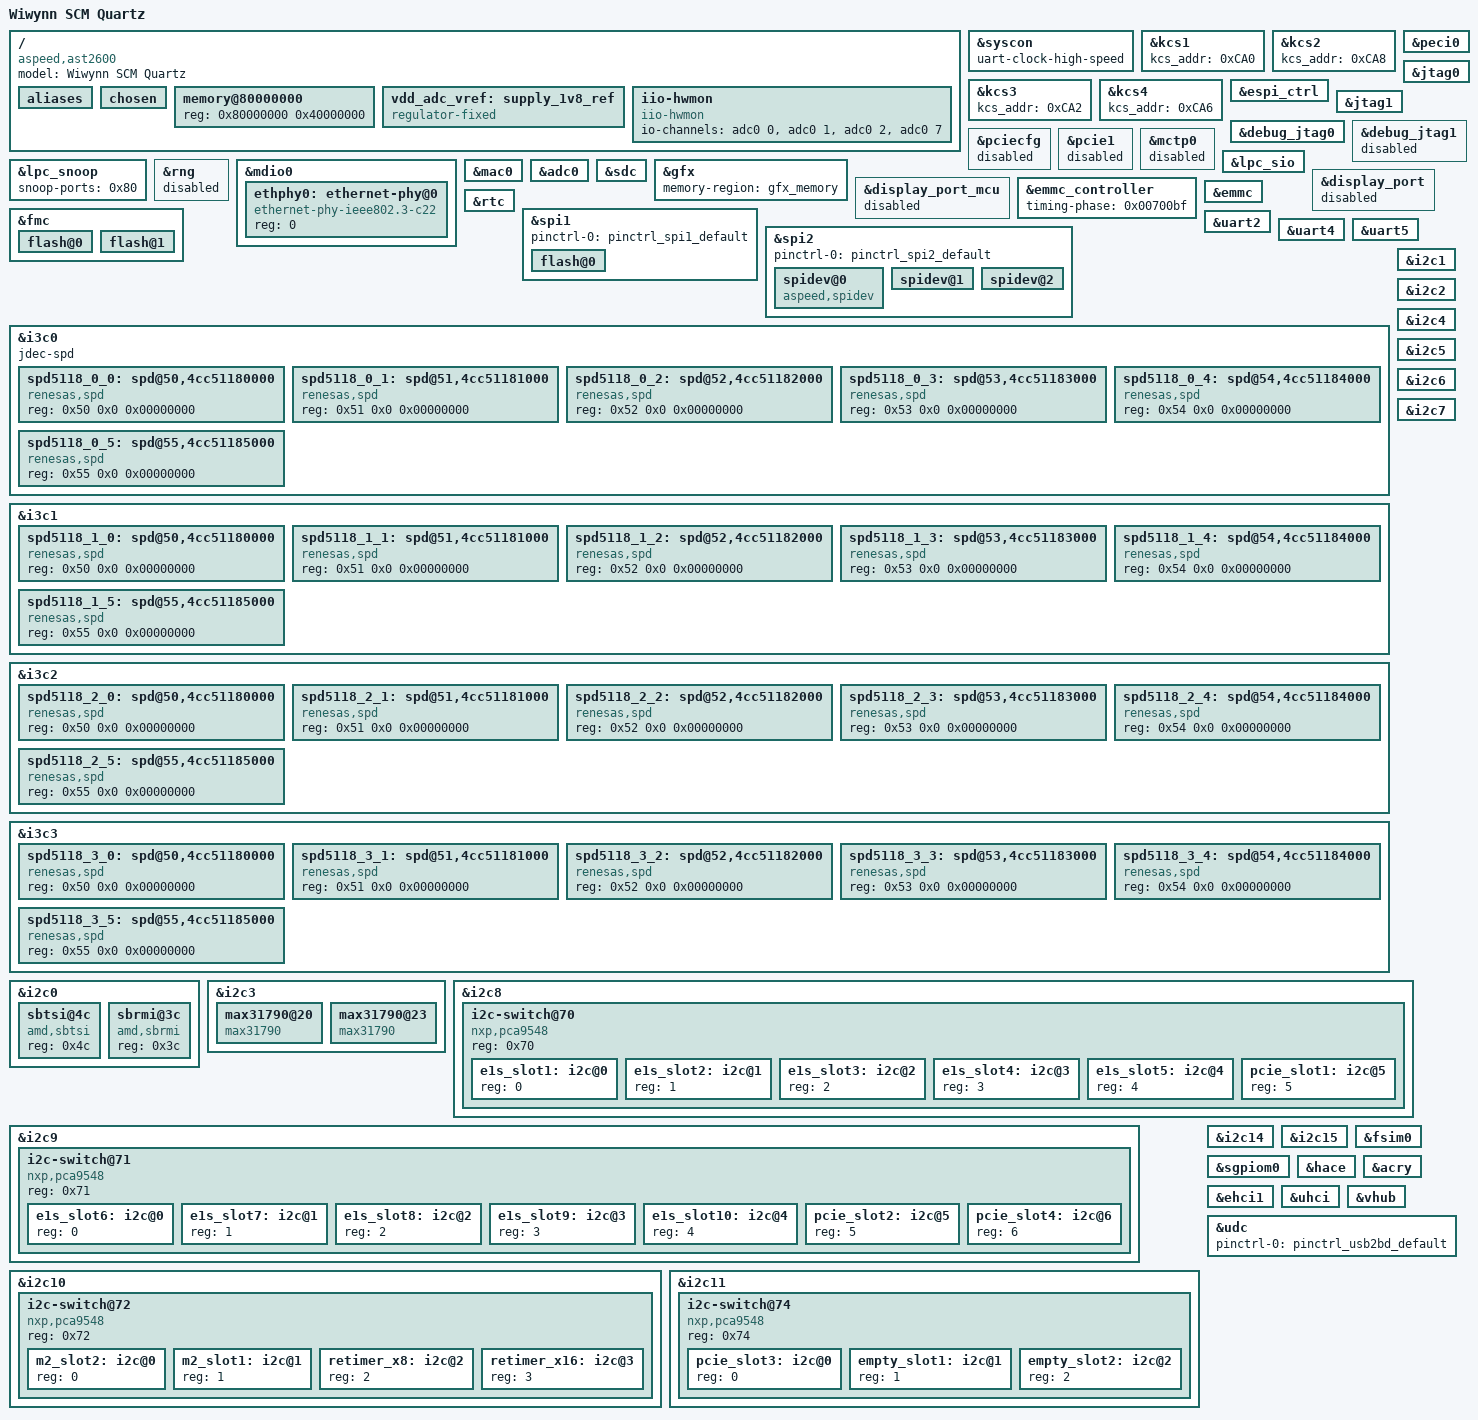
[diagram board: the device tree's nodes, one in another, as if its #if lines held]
// SPDX-License-Identifier: GPL-2.0-or-later
// Copyright 2019 IBM Corp.

/dts-v1/;

#include "aspeed-g6.dtsi"
#include <dt-bindings/gpio/aspeed-gpio.h>
#include <dt-bindings/i2c/i2c.h>

/ {
        model = "Wiwynn SCM Quartz";
        compatible = "aspeed,ast2600";

        aliases {
                serial0 = &uart1;
                serial1 = &uart2;
                serial2 = &uart3;
                serial3 = &uart4;
                serial4 = &uart5;
                i2c16 = &e1s_slot1;
                i2c17 = &e1s_slot2;
                i2c18 = &e1s_slot3;
                i2c19 = &e1s_slot4;
                i2c20 = &e1s_slot5;
                i2c21 = &pcie_slot1;
                i2c22 = &e1s_slot6;
                i2c23 = &e1s_slot7;
                i2c24 = &e1s_slot8;
                i2c25 = &e1s_slot9;
                i2c26 = &e1s_slot10;
                i2c27 = &pcie_slot2;
                i2c28 = &pcie_slot4;
                i2c29 = &m2_slot1;
                i2c30 = &m2_slot2;
                i2c31 = &retimer_x8;
                i2c32 = &retimer_x16;
                i2c33 = &pcie_slot3;
                i2c34 = &empty_slot1;
                i2c35 = &empty_slot2;
        };

        chosen {
		stdout-path = &uart5;
                bootargs = "console=ttyS4,115200n8";
        };

        memory@80000000 {
                device_type = "memory";
                reg = <0x80000000 0x40000000>;
        };
        vdd_adc_vref: supply_1v8_ref {
                compatible = "regulator-fixed";
                regulator-name = "adc-vref";
                regulator-min-microvolt = <1800000>;
                regulator-max-microvolt = <1800000>;
                regulator-always-on;
        };
    
        iio-hwmon {
                compatible = "iio-hwmon";
                io-channels = <&adc0 0>, <&adc0 1>, <&adc0 2>, <&adc0 7>;
        };

};

&syscon {
        uart-clock-high-speed;
        status = "okay";
};

#if 0
&lpc_pcc {
	dma-mode;
	memory-region = <&pcc_memory>;
    rec-mode = <0x1>;
    port-addr = <0x80>;
    port-addr-hbits-select = <0x1>;
    port-addr-xbits = <0x3>;
    status = "okay";
};

#endif

&kcs1 {
        kcs_addr = <0xCA0>;
        status = "okay";
};

&kcs2 {
        kcs_addr = <0xCA8>;
        status = "okay";
};

&kcs3 {
        kcs_addr = <0xCA2>;
        status = "okay";
};

&kcs4 {
        kcs_addr = <0xCA6>;
        status = "okay";
};

&peci0 {
        status = "okay";
};

#ifdef CONFIG_AMI
&espi_ctrl {
        status = "okay";

        perif,memcyc-src-addr = <0x98000000>;
        perif,memcyc-size = <0x10000>;
        perif,dma-mode;

        oob,dma-mode;
        oob,dma-tx-desc-num = <0x2>;
        oob,dma-rx-desc-num = <0x8>;

        flash,dma-mode;
        flash,safs-mode = <0x2>;

        aspeed,scu = <&syscon>;
};

&jtag0 {
        status = "okay";
};

&jtag1 {
        status = "okay";
};
#endif

#ifdef CONFIG_SPX_FEATURE_GLOBAL_AMD_REMOTE_DBG_SUPPORT
&debug_jtag0 {
        status = "okay";
};

&debug_jtag1 {
        status = "disabled";
};
#endif

#ifdef CONFIG_AMI
&pciecfg {
        status = "disabled";
};

&pcie1 {
        status = "disabled";
};

&mctp0 {
        tx-payload-bytes= <64>;
        rx-payload-bytes= <64>;
        status = "disabled";
};

&lpc_sio {
        status = "okay";
};
#endif

&lpc_snoop {
        snoop-ports = <0x80>;
        status = "okay";
};

&rng {
        status = "disabled";
};

&mdio0 {
        status = "okay";

        ethphy0: ethernet-phy@0 {
                compatible = "ethernet-phy-ieee802.3-c22";
                reg = <0>;
        };
};

&mac0 {
        status = "okay";

        phy-mode = "rgmii-rxid";
        phy-handle = <&ethphy0>;

        pinctrl-names = "default";
        pinctrl-0 = <&pinctrl_rgmii1_default>;
};

&adc0 {
        status = "okay";
        //aspeed,int-vref-microvolt = <1800000>;

        /*If you want to set external reference voltage(i.e. not 1.2V or 2.5V).
        You should add vref-supply property as below and set the microvolt 
        value at vdd_adc_vref node.*/
        vref-supply = <&vdd_adc_vref>;
        pinctrl-names = "default";
        pinctrl-0 = <&pinctrl_adc0_default &pinctrl_adc1_default
        &pinctrl_adc2_default &pinctrl_adc7_default>;
};

&sdc {
        status = "okay";
};

#ifdef CONFIG_AMI
&gfx {
        status = "okay";
        memory-region = <&gfx_memory>;
};

&display_port
{
        status = "disabled";
};

&display_port_mcu
{
        status = "disabled";
};

&emmc_controller {
        status = "okay";
        timing-phase = <0x00700bf>;
};

&emmc {
        status = "okay";
        non-removable;
        max-frequency = <100000000>;
        sdhci-drive-type = /bits/ 8 <3>;

        bus-width = <8>;
        pinctrl-0 = <&pinctrl_emmc_default
        &pinctrl_emmcg8_default>;
};
#endif

&rtc {
        status = "okay";
};

&fmc {
	status = "okay";

	flash@0 {
		status = "okay";
		m25p,fast-read;
		label = "bmc";
		spi-max-frequency = <133000000>;
#include "openbmc-flash-layout-64.dtsi"
	};

	flash@1 {
		status = "okay";
		m25p,fast-read;
		label = "alt-bmc";
		spi-max-frequency = <133000000>;
#include "openbmc-flash-layout-64-alt.dtsi"
	};
};

&spi1 {
	status = "okay";
	pinctrl-names = "default";
	pinctrl-0 = <&pinctrl_spi1_default>;

	flash@0 {
		status = "okay";
		m25p,fast-read;
		label = "bios";
		spi-max-frequency = <133000000>;
	};
};


&spi2 {
        status = "okay";
        pinctrl-names = "default";
        pinctrl-0 = <&pinctrl_spi2_default>;

        spidev@0 {
                status = "okay";
                compatible = "aspeed,spidev";
                reg = < 0 >;
                spi-max-frequency = <40000000>;
        };

        spidev@1 {
                status = "okay";
        };

        spidev@2 {
                status = "okay";
        };
};


&uart2 {
        status = "okay";
};

&uart4 {
        status = "okay";
};

&uart5 {
        status = "okay";
};

#ifdef CONFIG_SPX_FEATURE_DIMM_TEMP_MONITORING_SUPPORT
#ifdef CONFIG_SPX_FEATURE_DIMM_I2C_MODE
&i3c0 {
        status = "okay";
        jdec-spd;
        /* Renesas SPD5118 */
        spd5118_0_0: spd@50,4cc51180000 {
                compatible = "renesas,spd";
                reg = <0x50 0x0 0x00000000>;
        };
        
        /* Renesas SPD5118 */
        spd5118_0_1: spd@51,4cc51181000 {
                compatible = "renesas,spd";
                reg = <0x51 0x0 0x00000000>;
        };
        
        /* Renesas SPD5118 */
        spd5118_0_2: spd@52,4cc51182000 {
                compatible = "renesas,spd";
                reg = <0x52 0x0 0x00000000>;
        };
        
        /* Renesas SPD5118 */
        spd5118_0_3: spd@53,4cc51183000 {
                compatible = "renesas,spd";
                reg = <0x53 0x0 0x00000000>;
        };
        
        /* Renesas SPD5118 */
        spd5118_0_4: spd@54,4cc51184000 {
                compatible = "renesas,spd";
                reg = <0x54 0x0 0x00000000>;
        };
        
        /* Renesas SPD5118 */
        spd5118_0_5: spd@55,4cc51185000 {
                compatible = "renesas,spd";
                reg = <0x55 0x0 0x00000000>;
        };
};

&i3c1 {
        status = "okay";
        jdec-spd;
        pinctrl-names = "default";
        pinctrl-0 = <&pinctrl_i3c2_default>;
        
        /* Renesas SPD5118 */
        spd5118_1_0: spd@50,4cc51180000 {
                compatible = "renesas,spd";
                reg = <0x50 0x0 0x00000000>;
        };
        
        /* Renesas SPD5118 */
        spd5118_1_1: spd@51,4cc51181000 {
                compatible = "renesas,spd";
                reg = <0x51 0x0 0x00000000>;
        };
        
        /* Renesas SPD5118 */
        spd5118_1_2: spd@52,4cc51182000 {
                compatible = "renesas,spd";
                reg = <0x52 0x0 0x00000000>;
        };
        
        /* Renesas SPD5118 */
        spd5118_1_3: spd@53,4cc51183000 {
                compatible = "renesas,spd";
                reg = <0x53 0x0 0x00000000>;
        };
        
        /* Renesas SPD5118 */
        spd5118_1_4: spd@54,4cc51184000 {
                compatible = "renesas,spd";
                reg = <0x54 0x0 0x00000000>;
        };
        
        /* Renesas SPD5118 */
        spd5118_1_5: spd@55,4cc51185000 {
                compatible = "renesas,spd";
                reg = <0x55 0x0 0x00000000>;
        };
};

&i3c2 {
        status = "okay";
        jdec-spd;
        pinctrl-names = "default";
        pinctrl-0 = <&pinctrl_i3c3_default>;
        
        /* Renesas SPD5118 */
        spd5118_2_0: spd@50,4cc51180000 {
                compatible = "renesas,spd";
                reg = <0x50 0x0 0x00000000>;
        };
        
        /* Renesas SPD5118 */
        spd5118_2_1: spd@51,4cc51181000 {
                compatible = "renesas,spd";
                reg = <0x51 0x0 0x00000000>;
        };
        
        /* Renesas SPD5118 */
        spd5118_2_2: spd@52,4cc51182000 {
                compatible = "renesas,spd";
                reg = <0x52 0x0 0x00000000>;
        };
        
        /* Renesas SPD5118 */
        spd5118_2_3: spd@53,4cc51183000 {
                compatible = "renesas,spd";
                reg = <0x53 0x0 0x00000000>;
        };
        
        /* Renesas SPD5118 */
        spd5118_2_4: spd@54,4cc51184000 {
                compatible = "renesas,spd";
                reg = <0x54 0x0 0x00000000>;
        };
        
        /* Renesas SPD5118 */
        spd5118_2_5: spd@55,4cc51185000 {
                compatible = "renesas,spd";
                reg = <0x55 0x0 0x00000000>;
        };
};

&i3c3 {
        status = "okay";
        jdec-spd;
        pinctrl-names = "default";
        pinctrl-0 = <&pinctrl_i3c4_default>;

        /* Renesas SPD5118 */
        spd5118_3_0: spd@50,4cc51180000 {
                compatible = "renesas,spd";
                reg = <0x50 0x0 0x00000000>;
        };
        
        /* Renesas SPD5118 */
        spd5118_3_1: spd@51,4cc51181000 {
                compatible = "renesas,spd";
                reg = <0x51 0x0 0x00000000>;
        };
        
        /* Renesas SPD5118 */
        spd5118_3_2: spd@52,4cc51182000 {
                compatible = "renesas,spd";
                reg = <0x52 0x0 0x00000000>;
        };
        
        /* Renesas SPD5118 */
        spd5118_3_3: spd@53,4cc51183000 {
                compatible = "renesas,spd";
                reg = <0x53 0x0 0x00000000>;
        };
        
        /* Renesas SPD5118 */
        spd5118_3_4: spd@54,4cc51184000 {
                compatible = "renesas,spd";
                reg = <0x54 0x0 0x00000000>;
        };
        
        /* Renesas SPD5118 */
        spd5118_3_5: spd@55,4cc51185000 {
                compatible = "renesas,spd";
                reg = <0x55 0x0 0x00000000>;
        };
};
#else
&i3c0 {
        status = "okay";
        jdec-spd;
        /* Renesas SPD5118 */
        spd5118_0_0: spd@50,4cc51180000 {
                reg = <0x50 0x4cc 0x51180000>;
                assigned-address = <0x50>;
                dcr = <0xda>;
                bcr = <0x6>;
        };
        
        /* Renesas SPD5118 */
        spd5118_0_1: spd@51,4cc51181000 {
                reg = <0x51 0x4cc 0x51181000>;
                assigned-address = <0x51>;
                dcr = <0xda>;
                bcr = <0x6>;
        };
        
        /* Renesas SPD5118 */
        spd5118_0_2: spd@52,4cc51182000 {
                reg = <0x52 0x4cc 0x51182000>;
                assigned-address = <0x52>;
                dcr = <0xda>;
                bcr = <0x6>;
        };
        
        /* Renesas SPD5118 */
        spd5118_0_3: spd@53,4cc51183000 {
                reg = <0x53 0x4cc 0x51183000>;
                assigned-address = <0x53>;
                dcr = <0xda>;
                bcr = <0x6>;
        };
        
        /* Renesas SPD5118 */
        spd5118_0_4: spd@54,4cc51184000 {
                reg = <0x54 0x4cc 0x51184000>;
                assigned-address = <0x54>;
                dcr = <0xda>;
                bcr = <0x6>;
        };
        
        /* Renesas SPD5118 */
        spd5118_0_5: spd@55,4cc51185000 {
                reg = <0x55 0x4cc 0x51185000>;
                assigned-address = <0x55>;
                dcr = <0xda>;
                bcr = <0x6>;
        };
};

&i3c1 {
        status = "okay";
        jdec-spd;
        pinctrl-names = "default";
        pinctrl-0 = <&pinctrl_i3c2_default>;
        
         /* Renesas SPD5118 */
        spd5118_1_0: spd@50,4cc51180000 {
                reg = <0x50 0x4cc 0x51180000>;
                assigned-address = <0x50>;
                dcr = <0xda>;
                bcr = <0x6>;
        };
        
        /* Renesas SPD5118 */
        spd5118_1_1: spd@51,4cc51181000 {
                reg = <0x51 0x4cc 0x51181000>;
                assigned-address = <0x51>;
                dcr = <0xda>;
                bcr = <0x6>;
        };
        
        /* Renesas SPD5118 */
        spd5118_1_2: spd@52,4cc51182000 {
                reg = <0x52 0x4cc 0x51182000>;
                assigned-address = <0x52>;
                dcr = <0xda>;
                bcr = <0x6>;
        };
        
        /* Renesas SPD5118 */
        spd5118_1_3: spd@53,4cc51183000 {
                reg = <0x53 0x4cc 0x51183000>;
                assigned-address = <0x53>;
                dcr = <0xda>;
                bcr = <0x6>;
        };
        
        /* Renesas SPD5118 */
        spd5118_1_4: spd@54,4cc51184000 {
                reg = <0x54 0x4cc 0x51184000>;
                assigned-address = <0x54>;
                dcr = <0xda>;
                bcr = <0x6>;
        };
        
        /* Renesas SPD5118 */
        spd5118_1_5: spd@55,4cc51185000 {
                reg = <0x55 0x4cc 0x51185000>;
                assigned-address = <0x55>;
                dcr = <0xda>;
                bcr = <0x6>;
        };
};

&i3c2 {
        status = "okay";
        jdec-spd;
        pinctrl-names = "default";
        pinctrl-0 = <&pinctrl_i3c3_default>;
        
        /* Renesas SPD5118 */
        spd5118_2_0: spd@50,4cc51180000 {
                reg = <0x50 0x4cc 0x51180000>;
                assigned-address = <0x50>;
                dcr = <0xda>;
                bcr = <0x6>;
        };
        
        /* Renesas SPD5118 */
        spd5118_2_1: spd@51,4cc51181000 {
                reg = <0x51 0x4cc 0x51181000>;
                assigned-address = <0x51>;
                dcr = <0xda>;
                bcr = <0x6>;
        };
        
        /* Renesas SPD5118 */
        spd5118_2_2: spd@52,4cc51182000 {
                reg = <0x52 0x4cc 0x51182000>;
                assigned-address = <0x52>;
                dcr = <0xda>;
                bcr = <0x6>;
        };
        
        /* Renesas SPD5118 */
        spd5118_2_3: spd@53,4cc51183000 {
                reg = <0x53 0x4cc 0x51183000>;
                assigned-address = <0x53>;
                dcr = <0xda>;
                bcr = <0x6>;
        };
        
        /* Renesas SPD5118 */
        spd5118_2_4: spd@54,4cc51184000 {
                reg = <0x54 0x4cc 0x51184000>;
                assigned-address = <0x54>;
                dcr = <0xda>;
                bcr = <0x6>;
        };
        
        /* Renesas SPD5118 */
        spd5118_2_5: spd@55,4cc51185000 {
                reg = <0x55 0x4cc 0x51185000>;
                assigned-address = <0x55>;
                dcr = <0xda>;
                bcr = <0x6>;
        };
};

&i3c3 {
        status = "okay";
        jdec-spd;
        pinctrl-names = "default";
        pinctrl-0 = <&pinctrl_i3c4_default>;

        /* Renesas SPD5118 */
        spd5118_3_0: spd@50,4cc51180000 {
                reg = <0x50 0x4cc 0x51180000>;
                assigned-address = <0x50>;
                dcr = <0xda>;
                bcr = <0x6>;
        };
        
        /* Renesas SPD5118 */
        spd5118_3_1: spd@51,4cc51181000 {
                reg = <0x51 0x4cc 0x51181000>;
                assigned-address = <0x51>;
                dcr = <0xda>;
                bcr = <0x6>;
        };
        
        /* Renesas SPD5118 */
        spd5118_3_2: spd@52,4cc51182000 {
                reg = <0x52 0x4cc 0x51182000>;
                assigned-address = <0x52>;
                dcr = <0xda>;
                bcr = <0x6>;
        };
        
        /* Renesas SPD5118 */
        spd5118_3_3: spd@53,4cc51183000 {
                reg = <0x53 0x4cc 0x51183000>;
                assigned-address = <0x53>;
                dcr = <0xda>;
                bcr = <0x6>;
        };
        
        /* Renesas SPD5118 */
        spd5118_3_4: spd@54,4cc51184000 {
                reg = <0x54 0x4cc 0x51184000>;
                assigned-address = <0x54>;
                dcr = <0xda>;
                bcr = <0x6>;
        };
        
        /* Renesas SPD5118 */
        spd5118_3_5: spd@55,4cc51185000 {
                reg = <0x55 0x4cc 0x51185000>;
                assigned-address = <0x55>;
                dcr = <0xda>;
                bcr = <0x6>;
        };
};
#endif
#endif

&i2c0 {
        // P0 APML
        status = "okay";
        bus-frequency = <400000>;
        bus-mode = <0>;

        sbtsi@4c {
                compatible = "amd,sbtsi";
                reg = <0x4c>;
        };
        // sbrmi
        sbrmi@3c {
                compatible = "amd,sbrmi";
                reg = <0x3c>;
        };
};

&i2c1 {
        status = "okay";
        bus-mode = <0>;
        bus-frequency = <95000>;
};

&i2c2 {
        status = "okay";
        bus-mode = <0>;
        bus-frequency = <95000>;
};

&i2c3 {
        status = "okay";
        bus-mode = <0>;
        bus-frequency = <95000>;

        max31790@20 {
                compatible = "max31790";
                reg = <0x20>;
                #address-cells = <1>;
                #size-cells = <0>;
                fan-mode = "pwm";
                fanconfig = /bits/ 8 <0x08 0x08 0x18 0x18 0x18 0x18>;
        };

        max31790@23 {
                compatible = "max31790";
                reg = <0x23>;
                #address-cells = <2>;
                #size-cells = <0>;
                fan-mode = "fan";
                fanconfig = /bits/ 8 <0x19 0x19 0x19 0x19 0x19 0x19>;
        };
};

&i2c4 {
        status = "okay";
        bus-mode = <0>;
        bus-frequency = <95000>;
};

&i2c5 {
        status = "okay";
        bus-mode = <0>;
        bus-frequency = <95000>;
        multi-master;
};

&i2c6 {
        status = "okay";
        bus-mode = <0>;
        bus-frequency = <95000>;
};

&i2c7 {
        status = "okay";
        bus-mode = <0>;
        bus-frequency = <95000>;
};

&i2c8 {
        status = "okay";
        bus-mode = <0>;
        bus-frequency = <95000>;
        multi-master;

        i2c-switch@70 {
            compatible = "nxp,pca9548";
            #address-cells = <1>;
            #size-cells = <0>;
            reg = <0x70>;

            e1s_slot1: i2c@0{
                    #address-cells = <1>;
                    #size-cells = <0>;
                    reg = <0>;
            };

            e1s_slot2: i2c@1{
                    #address-cells = <1>;
                    #size-cells = <0>;
                    reg = <1>;
            };

            e1s_slot3: i2c@2{
                    #address-cells = <1>;
                    #size-cells = <0>;
                    reg = <2>;
            };

            e1s_slot4: i2c@3{
                    #address-cells = <1>;
                    #size-cells = <0>;
                    reg = <3>;
            };

            e1s_slot5: i2c@4{
                    #address-cells = <1>;
                    #size-cells = <0>;
                    reg = <4>;
            };

            pcie_slot1: i2c@5{
                    #address-cells = <1>;
                    #size-cells = <0>;
                    reg = <5>;
            };
        };
};

&i2c9 {
        status = "okay";
        bus-mode = <0>;
        bus-frequency = <95000>;
        multi-master;

        i2c-switch@71 {
            compatible = "nxp,pca9548";
            #address-cells = <1>;
            #size-cells = <0>;
            reg = <0x71>;

            e1s_slot6: i2c@0{
                    #address-cells = <1>;
                    #size-cells = <0>;
                    reg = <0>;
            };

            e1s_slot7: i2c@1{
                    #address-cells = <1>;
                    #size-cells = <0>;
                    reg = <1>;
            };

            e1s_slot8: i2c@2{
                    #address-cells = <1>;
                    #size-cells = <0>;
                    reg = <2>;
            };

            e1s_slot9: i2c@3{
                    #address-cells = <1>;
                    #size-cells = <0>;
                    reg = <3>;
            };

            e1s_slot10: i2c@4{
                    #address-cells = <1>;
                    #size-cells = <0>;
                    reg = <4>;
            };

            pcie_slot2: i2c@5{
                    #address-cells = <1>;
                    #size-cells = <0>;
                    reg = <5>;
            };

            pcie_slot4: i2c@6{
                    #address-cells = <1>;
                    #size-cells = <0>;
                    reg = <6>;
            };
        };
};

&i2c10 {
        status = "okay";
        bus-mode = <0>;
        bus-frequency = <95000>;
        multi-master;

        i2c-switch@72 {
            compatible = "nxp,pca9548";
            #address-cells = <1>;
            #size-cells = <0>;
            reg = <0x72>;

            m2_slot2: i2c@0{
                    #address-cells = <1>;
                    #size-cells = <0>;
                    reg = <0>;
            };

            m2_slot1: i2c@1{
                    #address-cells = <1>;
                    #size-cells = <0>;
                    reg = <1>;
            };

            retimer_x8: i2c@2{
                    #address-cells = <1>;
                    #size-cells = <0>;
                    reg = <2>;
            };

            retimer_x16: i2c@3{
                    #address-cells = <1>;
                    #size-cells = <0>;
                    reg = <3>;
            };
        };
};

&i2c11 {
        status = "okay";
        bus-mode = <0>;
        bus-frequency = <95000>;
        multi-master;

        i2c-switch@74 {
            compatible = "nxp,pca9548";
            #address-cells = <1>;
            #size-cells = <0>;
            reg = <0x74>;

            pcie_slot3: i2c@0{
                    #address-cells = <1>;
                    #size-cells = <0>;
                    reg = <0>;
            };

            empty_slot1: i2c@1{
                    #address-cells = <1>;
                    #size-cells = <0>;
                    reg = <1>;
            };

            empty_slot2: i2c@2{
                    #address-cells = <1>;
                    #size-cells = <0>;
                    reg = <2>;
            };
        };
};

&i2c14 {
        status = "okay";
        bus-mode = <0>;
        bus-frequency = <95000>;
};

&i2c15 {
        status = "okay";
        bus-mode = <0>;
        bus-frequency = <95000>;
        multi-master;
};

&fsim0 {
        status = "okay";
};
&sgpiom0 {
        status = "okay";
};

#ifdef CONFIG_AMI
&hace {
        status = "okay";
};

&acry {
        status = "okay";
};
#endif

#ifdef CONFIG_SPX_FEATURE_USB_PORT_B_HOST_SUPPORT
&ehci1 {
        status = "okay";
};

&uhci {
        status = "okay";
};
#endif

&vhub {
        status = "okay";
};

#ifdef CONFIG_SPX_FEATURE_USB_PORT_B_SUPPORT
&udc {
        status = "okay";
        pinctrl-names = "default";
        pinctrl-0 = <&pinctrl_usb2bd_default>;
};
#endif
/*
&wdt1 {
        status = "okay";
        aspeed,reset-type = "none";

        pinctrl-names = "default";
        pinctrl-0 = <&pinctrl_wdtrst1_default>;
};

&wdt2 {
        status = "okay";
        timeout-sec = <60>;
        aspeed,external-signal;

        pinctrl-names = "default";
        pinctrl-0 = <&pinctrl_wdtrst2_default>;
};
*/
// #include "legacy.dtsi" /* For Legacy AMI Drivers */

